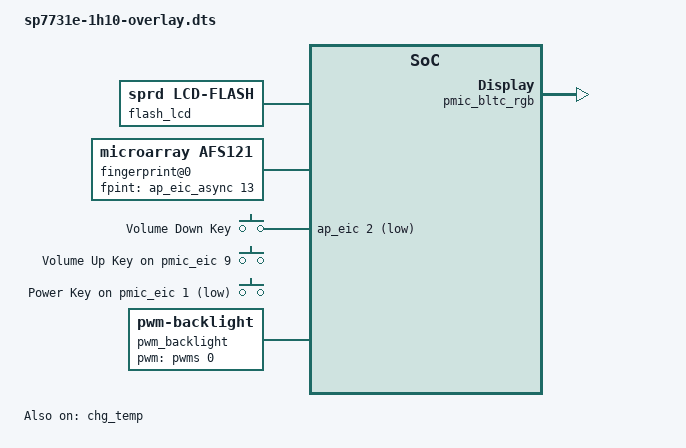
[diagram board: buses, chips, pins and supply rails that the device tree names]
/*
 * Spreadtrum sharkle sp7731e board DTS file
 *
 * Copyright (C) 2018, Spreadtrum Communications Inc.
 *
 * This file is licensed under a dual GPLv2 or X11 license.
 */
/dts-v1/;
/plugin/;

/ {
	/*
	* When create a new node, we should use the key word __overlay__,
	* otherwise u-boot can not analyze it.
	*/

	fragment {
		target-path = "/";
		__overlay__ {
			sprd_overlay {
				compatible = "sprd,overlay";
				string = "spreadtrum overlay test!";
			};

			flash_lcd: flash-lcd {
				compatible = "sprd,lcd-flash";
				sprd,dispc = <&dispc0>;
				sprd,backlight = <&pwm_backlight>;
				status = "okay";
			};
			fingerprint@0 {
				compatible = "microarray,afs121";
				fpint-gpios = <&ap_eic_async 13 0>;
			};

			gpio-keys {
				compatible = "gpio-keys";
				input-name = "sprd-gpio-keys";
				status = "okay";

				key-volumedown {
					label = "Volume Down Key";
					linux,code = <114>;
					gpios = <&ap_eic 2 1>;
					debounce-interval = <2>;
					gpio-key,wakeup;
					gpio-key,level-trigger;
				};

				key-volumeup {
					label = "Volume Up Key";
					linux,code = <115>;
					gpios = <&pmic_eic 9 0>;
					debounce-interval = <2>;
					gpio-key,wakeup;
					gpio-key,level-trigger;
				};

				key-power {
					label = "Power Key";
					linux,code = <116>;
					gpios = <&pmic_eic 1 1>;
					debounce-interval = <2>;
					gpio-key,wakeup;
					gpio-key,level-trigger;
				};
			};
			pwm_backlight: sprd_backlight {
				compatible = "pwm-backlight";
				pwms = <&pwms 0 20000>;
				pwm-names = "backlight";
				brightness_max = <256>;
				brightness-levels = <
								  3   3   3   3
					  3   3   3   3   3   3   3   5   7   9
					 10  11  12  13  14  15  16  17  18  19
					 20  21  22  23  24  25  26  27  28  29
					 30  31  32  33  34  35  36  37  38  39
					 40  41  42  43  44  45  46  47  48  49
					 50  51  52  53  54  55  56  57  58  59
					 60  61  62  63  64  65  66  67  68  69
					 70  71  72  73  74  75  76  77  78  79
					 80  81  82  83  84  85  86  87  88  89
					 90  91  92  93  94  95  96  97  98  99
					100 101 102 103 104 105 106 107 108 109
					110 111 112 113 114 115 116 117 118 119
					120 121 122 123 124 125 126 127 128 129
					130 131 132 133 134 135 136 137 138 139
					140 141 142 143 144 145 146 147 148 149
					150 151 152 153 154 155 156 157 158 159
					160 161 162 163 164 165 166 167 168 169
					170 171 172 173 174 175 176 177 178 179
					180 181 182 183 184 185 186 187 188 189
					190 191 192 193 194 195 196 197 198 199
					200 201 202 203 204 205 206 207 208 209
					210 211 212 213 214 215 216 217 218 219
					220 221 222 223 224 225 226 227 228 229
					230 231 232 233 234 235 236 237 238 239
					240 241 242 243 244 245 246 247 248 249
					250 251
					>;
				default-brightness-level = <29>;
			};
		};
	};
};

/*
 * Sample code. Google strongly recommends you do not use fragment@x and
 * syntax __overlay__, and instead use the reference syntax
*/
&memory {
	compatible = "sprd,memory-dtbo";
};

&pmic_bltc_rgb {
	status = "okay";
};

&ddr_dfs {
	sprd-scene = "lcdon", "lcdoff", "camlow", "camhigh";
	sprd-freq = <256 256 384 533>;
	overflow = <6140000 9216000 4294967295 4294967295>;
	underflow = <1 6040000 8216000 4294967295>;
};

&battery {
	io-channels = <&pmic_adc 0>,<&pmic_adc 4>,<&pmic_adc 5>,
			<&pmic_adc 14>;
	io-channel-names = "adc_batt_id","adc_temp","adc_vbat",
			"adc_vchg";
	temp-support = <1>;
	adp-cdp-cur = <700>;
	adp-dcp-cur = <700>;
	adp-sdp-cur = <500>;
	chg-end-vol = <4350>;
	chg-end-vol-check = <4330>;
	chg-bat-safety-vol = <4430>;
	rechg-vol = <4270>;
	rsense-real = <100>;
	bat-id-list = <47 270>; /* battery id kohm fenghua:47K weike:270K */
	rint = <278>;
	cnom = <2092>;
	ocv-tab-vol = <4321 4245 4184 4128 4076 4022 3977
			3938 3895 3849 3817 3796 3782 3775
			3772 3760 3740 3709 3618 3539 3400>;
	rint-1 = <183>;
	cnom-1 = <2030>;
	ocv-tab-vol-1 = <4326 4254 4195 4140 4088 4041 3986
			3949 3906 3861 3830 3807 3791 3779
			3772 3758 3742 3722 3692 3628 3400>;
	ocv-tab-cap = <100  95   90   85   80   75   70
			65   60   55   50   45   40   35
			30   25   20   15   10   5    0>;
	/*30mohm,if temp-table-mode = <1>, use it*/
	temp-comp-res = <30>;
	temp-tab-val = <1124 1104 1079 1047 1010 967
			917 861 801 738 672 607
			543 482 425 372 325 282 243>;
	/* temperature + 1000,750 = 1000 + (-250)*/
	temp-tab-temp = <750 800 850 900 950 1000
			1050 1100 1150 1200 1250 1300
			1350 1400 1450 1500 1550 1600 1650>;
	jeita-temp-tab = <1000 1050 1150 1450 1550>;
	jeita-temp-recovery-tab = <1030 1080 1170 1420 1520>;
	jeita-cur-tab = <0 600 600 0x7fff 600 0>;
	jeita-cccv-tab = <4350 4350 4350 4350 4100 4100>;
	batt_full_design_capacity = <2000>;
};

&chg_temp {
	status = "okay";
};
